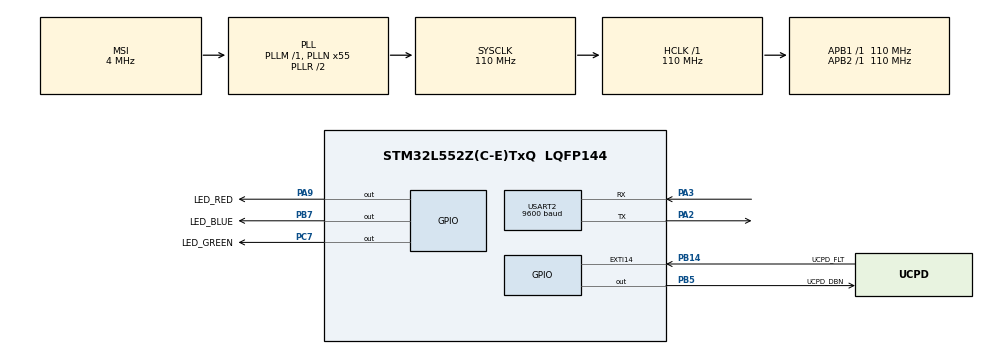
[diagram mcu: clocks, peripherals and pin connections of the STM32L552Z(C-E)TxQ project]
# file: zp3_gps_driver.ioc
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Dma.Request0=USART2_RX
Dma.USART2_RX.0.Channel_PRIV_NPRIV=DMA_CHANNEL_NPRIV_DISABLE
Dma.USART2_RX.0.Direction=DMA_PERIPH_TO_MEMORY
Dma.USART2_RX.0.EventEnable=DISABLE
Dma.USART2_RX.0.Instance=DMA1_Channel1
Dma.USART2_RX.0.MemDataAlignment=DMA_MDATAALIGN_BYTE
Dma.USART2_RX.0.MemInc=DMA_MINC_ENABLE
Dma.USART2_RX.0.Mode=DMA_CIRCULAR
Dma.USART2_RX.0.PeriphDataAlignment=DMA_PDATAALIGN_BYTE
Dma.USART2_RX.0.PeriphInc=DMA_PINC_DISABLE
Dma.USART2_RX.0.Polarity=HAL_DMAMUX_REQ_GEN_RISING
Dma.USART2_RX.0.Priority=DMA_PRIORITY_LOW
Dma.USART2_RX.0.RequestNumber=1
Dma.USART2_RX.0.SignalID=NONE
Dma.USART2_RX.0.SyncEnable=DISABLE
Dma.USART2_RX.0.SyncPolarity=HAL_DMAMUX_SYNC_NO_EVENT
Dma.USART2_RX.0.SyncRequestNumber=1
Dma.USART2_RX.0.SyncSignalID=NONE
Mcu.Family=STM32L5
Mcu.Name=STM32L552Z(C-E)TxQ
Mcu.Package=LQFP144
Mcu.TrustZone=disable
NVIC.DMA1_Channel1_IRQn=true\:0\:0\:false\:false\:true\:false\:true\:true
NVIC.PriorityGroup=NVIC_PRIORITYGROUP_3
PA11.Signal=USB_DM
PA13\ (JTMS/SWDIO).Signal=DEBUG_JTMS-SWDIO
PA14\ (JTCK/SWCLK).Signal=DEBUG_JTCK-SWCLK
PA15\ (JTDI).Signal=UCPD1_CC1
PA2.Mode=Asynchronous
PA2.Signal=USART2_TX
PA3.Mode=Asynchronous
PA3.Signal=USART2_RX
PA9.GPIO_Label=LED_RED
PA9.Signal=GPIO_Output
PB14.GPIO_Label=UCPD_FLT
PB14.Signal=GPXTI14
PB15.Signal=UCPD1_CC2
PB3\ (JTDO/TRACESWO).Signal=DEBUG_JTDO-SWO
PB5.GPIO_Label=UCPD_DBN
PB5.Signal=GPIO_Output
PB7.GPIO_Label=LED_BLUE
PB7.Signal=GPIO_Output
PC13.GPIO_Label=USER_BUTTON
PC13.Signal=PWR_WKUP2
PC14-OSC32_IN\ (PC14).Signal=RCC_OSC32_IN
PC15-OSC32_OUT\ (PC15).Signal=RCC_OSC32_OUT
PC2.GPIO_Label=VBUS_SENSE
PC2.Signal=ADCx_IN3
PC7.GPIO_Label=LED_GREEN
PC7.Signal=GPIO_Output
PG7.GPIO_Label=LPUART1_TX [ST-LINK_VCP_RX]
PG7.Signal=LPUART1_TX
PG8.GPIO_Label=LPUART1_RX [ST-LINK_VCP_TX]
PG8.Signal=LPUART1_RX
ProjectManager.HeapSize=0x200
ProjectManager.StackSize=0x400
ProjectManager.TargetToolchain=STM32CubeIDE
RCC.ADCCLockSelection=RCC_ADCCLKSOURCE_SYSCLK
RCC.ADCFreq_Value=110000000
RCC.AHBFreq_Value=110000000
RCC.APB1Freq_Value=110000000
RCC.APB1TimFreq_Value=110000000
RCC.APB2Freq_Value=110000000
RCC.APB2TimFreq_Value=110000000
RCC.CK48CLockSelection=RCC_USBCLKSOURCE_HSI48
RCC.CortexFreq_Value=110000000
RCC.HCLKFreq_Value=110000000
RCC.HSE_VALUE=8000000
RCC.HSI48_VALUE=48000000
RCC.HSI_VALUE=16000000
RCC.LSE_VALUE=32768
RCC.MSI_VALUE=4000000
RCC.PLLN=55
RCC.PLLSAI1N=24
RCC.RTCClockSelection=RCC_RTCCLKSOURCE_LSE
RCC.SYSCLKFreq_VALUE=110000000
RCC.SYSCLKSource=RCC_SYSCLKSOURCE_PLLCLK
RCC.USBFreq_Value=48000000
RCC.VCOOutputFreq_Value=220000000
SH.ADCx_IN3.0=ADC1_IN3
USART2.BaudRate=9600
USART2.VirtualMode-Asynchronous=VM_ASYNC
VP_ICACHE_VS_ICACHE.Mode=DirectMappedCache
VP_PWR_VS_DBSignals.Mode=DisableDeadBatterySignals
VP_PWR_VS_SECSignals.Mode=Security/Privilege
board=NUCLEO-L552ZE-Q

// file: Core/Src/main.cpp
/* USER CODE BEGIN Header */
/**
  ******************************************************************************
  * @file           : main.c
  * @brief          : Main program body
  ******************************************************************************
  * @attention
  *
  * Copyright (c) 2025 STMicroelectronics.
  * All rights reserved.
  *
  * This software is licensed under terms that can be found in the LICENSE file
  * in the root directory of this software component.
  * If no LICENSE file comes with this software, it is provided AS-IS.
  *
  ******************************************************************************
  */
/* USER CODE END Header */
#include "main.h"

/* USER CODE BEGIN Includes */
#include "zp_d_gps.hpp"
/* USER CODE END Includes */

UART_HandleTypeDef huart2;
DMA_HandleTypeDef hdma_usart2_rx;

void SystemClock_Config(void);
static void MX_GPIO_Init(void);
static void MX_DMA_Init(void);
static void MX_ICACHE_Init(void);
static void MX_USART2_UART_Init(void);

/* USER CODE BEGIN 0 */

GPS* gps = new GPS (&huart2);

/* USER CODE END 0 */

int main(void)
{

  /* MCU Configuration--------------------------------------------------------*/

  /* Reset of all peripherals, Initializes the Flash interface and the Systick. */
  HAL_Init();

  /* Configure the system clock */
  SystemClock_Config();

  /* Initialize all configured peripherals */
  MX_GPIO_Init();
  MX_DMA_Init();
  MX_ICACHE_Init();
  MX_USART2_UART_Init();
  /* USER CODE BEGIN 2 */
  int initSuccess = gps->init();
  /* USER CODE END 2 */

  /* Infinite loop */
  while (1)
  {

  }
}

void SystemClock_Config(void)
{
  RCC_OscInitTypeDef RCC_OscInitStruct = {0};
  RCC_ClkInitTypeDef RCC_ClkInitStruct = {0};

  /** Configure the main internal regulator output voltage
  */
  if (HAL_PWREx_ControlVoltageScaling(PWR_REGULATOR_VOLTAGE_SCALE0) != HAL_OK)
  {
    Error_Handler();
  }

  /** Initializes the RCC Oscillators according to the specified parameters
  * in the RCC_OscInitTypeDef structure.
  */
  RCC_OscInitStruct.OscillatorType = RCC_OSCILLATORTYPE_MSI;
  RCC_OscInitStruct.MSIState = RCC_MSI_ON;
  RCC_OscInitStruct.MSICalibrationValue = RCC_MSICALIBRATION_DEFAULT;
  RCC_OscInitStruct.MSIClockRange = RCC_MSIRANGE_6;
  RCC_OscInitStruct.PLL.PLLState = RCC_PLL_ON;
  RCC_OscInitStruct.PLL.PLLSource = RCC_PLLSOURCE_MSI;
  RCC_OscInitStruct.PLL.PLLM = 1;
  RCC_OscInitStruct.PLL.PLLN = 55;
  RCC_OscInitStruct.PLL.PLLP = RCC_PLLP_DIV7;
  RCC_OscInitStruct.PLL.PLLQ = RCC_PLLQ_DIV2;
  RCC_OscInitStruct.PLL.PLLR = RCC_PLLR_DIV2;
  if (HAL_RCC_OscConfig(&RCC_OscInitStruct) != HAL_OK)
  {
    Error_Handler();
  }

  /** Initializes the CPU, AHB and APB buses clocks
  */
  RCC_ClkInitStruct.ClockType = RCC_CLOCKTYPE_HCLK|RCC_CLOCKTYPE_SYSCLK
                              |RCC_CLOCKTYPE_PCLK1|RCC_CLOCKTYPE_PCLK2;
  RCC_ClkInitStruct.SYSCLKSource = RCC_SYSCLKSOURCE_PLLCLK;
  RCC_ClkInitStruct.AHBCLKDivider = RCC_SYSCLK_DIV1;
  RCC_ClkInitStruct.APB1CLKDivider = RCC_HCLK_DIV1;
  RCC_ClkInitStruct.APB2CLKDivider = RCC_HCLK_DIV1;

  if (HAL_RCC_ClockConfig(&RCC_ClkInitStruct, FLASH_LATENCY_5) != HAL_OK)
  {
    Error_Handler();
  }
}

static void MX_ICACHE_Init(void)
{

  /** Enable instruction cache in 1-way (direct mapped cache)
  */
  if (HAL_ICACHE_ConfigAssociativityMode(ICACHE_1WAY) != HAL_OK)
  {
    Error_Handler();
  }
  if (HAL_ICACHE_Enable() != HAL_OK)
  {
    Error_Handler();
  }

}

static void MX_USART2_UART_Init(void)
{

  huart2.Instance = USART2;
  huart2.Init.BaudRate = 9600;
  huart2.Init.WordLength = UART_WORDLENGTH_8B;
  huart2.Init.StopBits = UART_STOPBITS_1;
  huart2.Init.Parity = UART_PARITY_NONE;
  huart2.Init.Mode = UART_MODE_TX_RX;
  huart2.Init.HwFlowCtl = UART_HWCONTROL_NONE;
  huart2.Init.OverSampling = UART_OVERSAMPLING_16;
  huart2.Init.OneBitSampling = UART_ONE_BIT_SAMPLE_DISABLE;
  huart2.Init.ClockPrescaler = UART_PRESCALER_DIV1;
  huart2.AdvancedInit.AdvFeatureInit = UART_ADVFEATURE_NO_INIT;
  if (HAL_UART_Init(&huart2) != HAL_OK)
  {
    Error_Handler();
  }
  if (HAL_UARTEx_SetTxFifoThreshold(&huart2, UART_TXFIFO_THRESHOLD_1_8) != HAL_OK)
  {
    Error_Handler();
  }
  if (HAL_UARTEx_SetRxFifoThreshold(&huart2, UART_RXFIFO_THRESHOLD_1_8) != HAL_OK)
  {
    Error_Handler();
  }
  if (HAL_UARTEx_DisableFifoMode(&huart2) != HAL_OK)
  {
    Error_Handler();
  }

}

static void MX_DMA_Init(void)
{

  /* DMA controller clock enable */
  __HAL_RCC_DMAMUX1_CLK_ENABLE();
  __HAL_RCC_DMA1_CLK_ENABLE();

  /* DMA interrupt init */
  /* DMA1_Channel1_IRQn interrupt configuration */
  HAL_NVIC_SetPriority(DMA1_Channel1_IRQn, 0, 0);
  HAL_NVIC_EnableIRQ(DMA1_Channel1_IRQn);

}

static void MX_GPIO_Init(void)
{
  GPIO_InitTypeDef GPIO_InitStruct = {0};

  /* GPIO Ports Clock Enable */
  __HAL_RCC_GPIOC_CLK_ENABLE();
  __HAL_RCC_GPIOA_CLK_ENABLE();
  __HAL_RCC_GPIOB_CLK_ENABLE();
  __HAL_RCC_GPIOG_CLK_ENABLE();
  HAL_PWREx_EnableVddIO2();

  /*Configure GPIO pin Output Level */
  HAL_GPIO_WritePin(LED_GREEN_GPIO_Port, LED_GREEN_Pin, GPIO_PIN_RESET);

  /*Configure GPIO pin Output Level */
  HAL_GPIO_WritePin(LED_RED_GPIO_Port, LED_RED_Pin, GPIO_PIN_RESET);

  /*Configure GPIO pin Output Level */
  HAL_GPIO_WritePin(GPIOB, UCPD_DBN_Pin|LED_BLUE_Pin, GPIO_PIN_RESET);

  /*Configure GPIO pin : VBUS_SENSE_Pin */
  GPIO_InitStruct.Pin = VBUS_SENSE_Pin;
  GPIO_InitStruct.Mode = GPIO_MODE_ANALOG;
  GPIO_InitStruct.Pull = GPIO_NOPULL;
  HAL_GPIO_Init(VBUS_SENSE_GPIO_Port, &GPIO_InitStruct);

  /*Configure GPIO pin : UCPD_FLT_Pin */
  GPIO_InitStruct.Pin = UCPD_FLT_Pin;
  GPIO_InitStruct.Mode = GPIO_MODE_IT_RISING;
  GPIO_InitStruct.Pull = GPIO_NOPULL;
  HAL_GPIO_Init(UCPD_FLT_GPIO_Port, &GPIO_InitStruct);

  /*Configure GPIO pin : PB15 */
  GPIO_InitStruct.Pin = GPIO_PIN_15;
  GPIO_InitStruct.Mode = GPIO_MODE_ANALOG;
  GPIO_InitStruct.Pull = GPIO_NOPULL;
  HAL_GPIO_Init(GPIOB, &GPIO_InitStruct);

  /*Configure GPIO pins : LPUART1_TX_Pin LPUART1_RX_Pin */
  GPIO_InitStruct.Pin = LPUART1_TX_Pin|LPUART1_RX_Pin;
  GPIO_InitStruct.Mode = GPIO_MODE_AF_PP;
  GPIO_InitStruct.Pull = GPIO_NOPULL;
  GPIO_InitStruct.Speed = GPIO_SPEED_FREQ_LOW;
  GPIO_InitStruct.Alternate = GPIO_AF8_LPUART1;
  HAL_GPIO_Init(GPIOG, &GPIO_InitStruct);

  /*Configure GPIO pin : LED_GREEN_Pin */
  GPIO_InitStruct.Pin = LED_GREEN_Pin;
  GPIO_InitStruct.Mode = GPIO_MODE_OUTPUT_PP;
  GPIO_InitStruct.Pull = GPIO_NOPULL;
  GPIO_InitStruct.Speed = GPIO_SPEED_FREQ_LOW;
  HAL_GPIO_Init(LED_GREEN_GPIO_Port, &GPIO_InitStruct);

  /*Configure GPIO pin : LED_RED_Pin */
  GPIO_InitStruct.Pin = LED_RED_Pin;
  GPIO_InitStruct.Mode = GPIO_MODE_OUTPUT_PP;
  GPIO_InitStruct.Pull = GPIO_NOPULL;
  GPIO_InitStruct.Speed = GPIO_SPEED_FREQ_LOW;
  HAL_GPIO_Init(LED_RED_GPIO_Port, &GPIO_InitStruct);

  /*Configure GPIO pin : PA11 */
  GPIO_InitStruct.Pin = GPIO_PIN_11;
  GPIO_InitStruct.Mode = GPIO_MODE_AF_PP;
  GPIO_InitStruct.Pull = GPIO_NOPULL;
  GPIO_InitStruct.Speed = GPIO_SPEED_FREQ_LOW;
  GPIO_InitStruct.Alternate = GPIO_AF10_USB;
  HAL_GPIO_Init(GPIOA, &GPIO_InitStruct);

  /*Configure GPIO pin : PA15 */
  GPIO_InitStruct.Pin = GPIO_PIN_15;
  GPIO_InitStruct.Mode = GPIO_MODE_ANALOG;
  GPIO_InitStruct.Pull = GPIO_NOPULL;
  HAL_GPIO_Init(GPIOA, &GPIO_InitStruct);

  /*Configure GPIO pins : UCPD_DBN_Pin LED_BLUE_Pin */
  GPIO_InitStruct.Pin = UCPD_DBN_Pin|LED_BLUE_Pin;
  GPIO_InitStruct.Mode = GPIO_MODE_OUTPUT_PP;
  GPIO_InitStruct.Pull = GPIO_NOPULL;
  GPIO_InitStruct.Speed = GPIO_SPEED_FREQ_LOW;
  HAL_GPIO_Init(GPIOB, &GPIO_InitStruct);

}

/* USER CODE BEGIN 4 */

extern "C" {
	void HAL_UARTEx_RxEventCallback(UART_HandleTypeDef *huart, uint16_t Size) {
		int success = -1;
		if (&huart2 == huart) {
			success = gps->processGPSData();
		}
	}
}

/* USER CODE END 4 */

void Error_Handler(void)
{
  __disable_irq();
  while (1)
  {
  }
}
